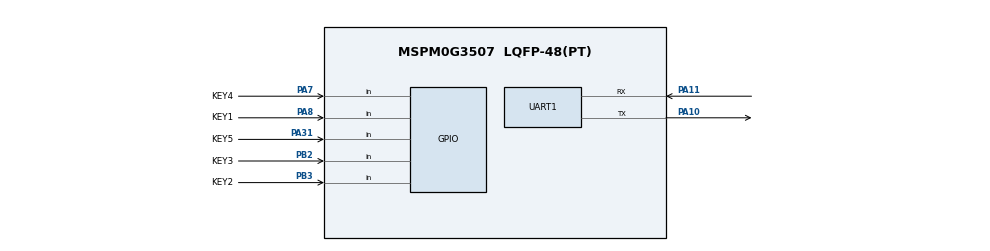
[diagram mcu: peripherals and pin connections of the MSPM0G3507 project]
/**
 * AI AGENTS: Do not edit this file directly. There is no validation or error feedback when
 * editing manually — mistakes will be silent until the file is loaded in SysConfig.
 * Use the SysConfig MCP server instead to make changes with immediate error reporting.
 *
 * These arguments were used when this file was generated. They will be automatically applied on subsequent loads
 * via the GUI or CLI. Run CLI with '--help' for additional information on how to override these arguments.
 * @cliArgs --device "MSPM0G350X" --part "Default" --package "LQFP-48(PT)" --product "mspm0_sdk@2.05.00.05"
 * @v2CliArgs --device "MSPM0G3507" --package "LQFP-48(PT)" --product "mspm0_sdk@2.05.00.05"
 * @versions {"tool":"1.28.0+4712"}
 */

/**
 * Import the modules used in this configuration.
 */
const ADC12  = scripting.addModule("/ti/driverlib/ADC12", {}, false);
const ADC121 = ADC12.addInstance();
const ADC122 = ADC12.addInstance();
const Board  = scripting.addModule("/ti/driverlib/Board");
const DAC12  = scripting.addModule("/ti/driverlib/DAC12");
const DMA    = scripting.addModule("/ti/driverlib/DMA");
const GPIO   = scripting.addModule("/ti/driverlib/GPIO", {}, false);
const GPIO1  = GPIO.addInstance();
const PWM    = scripting.addModule("/ti/driverlib/PWM", {}, false);
const PWM1   = PWM.addInstance();
const SYSCTL = scripting.addModule("/ti/driverlib/SYSCTL");
const TIMER  = scripting.addModule("/ti/driverlib/TIMER", {}, false);
const TIMER1 = TIMER.addInstance();
const TIMER2 = TIMER.addInstance();
const UART   = scripting.addModule("/ti/driverlib/UART", {}, false);
const UART1  = UART.addInstance();
const VREF   = scripting.addModule("/ti/driverlib/VREF");

/**
 * Write custom configuration values to the imported modules.
 */
const gate8  = system.clockTree["MFPCLKGATE"];
gate8.enable = true;

ADC121.$name                          = "ADC12_0";
ADC121.repeatMode                     = true;
ADC121.trigSrc                        = "DL_ADC12_TRIG_SRC_EVENT";
ADC121.adcMem0chansel                 = "DL_ADC12_INPUT_CHAN_7";
ADC121.adcMem0vref                    = "DL_ADC12_REFERENCE_VOLTAGE_INTREF";
ADC121.sampleTime0                    = "500ns";
ADC121.powerDownMode                  = "DL_ADC12_POWER_DOWN_MODE_MANUAL";
ADC121.configureDMA                   = true;
ADC121.sampCnt                        = 1;
ADC121.enabledDMATriggers             = ["DL_ADC12_DMA_MEM0_RESULT_LOADED"];
ADC121.enabledInterrupts              = ["DL_ADC12_INTERRUPT_DMA_DONE"];
ADC121.subChanID                      = 1;
ADC121.peripheral.$assign             = "ADC0";
ADC121.peripheral.adcPin7.$assign     = "PA22";
ADC121.adcPin7Config.$name            = "ti_driverlib_gpio_GPIOPinGeneric0";
ADC121.DMA_CHANNEL.$name              = "DMA_CH0";
ADC121.DMA_CHANNEL.addressMode        = "f2b";
ADC121.DMA_CHANNEL.srcLength          = "HALF_WORD";
ADC121.DMA_CHANNEL.dstLength          = "HALF_WORD";
ADC121.DMA_CHANNEL.transferMode       = "FULL_CH_REPEAT_SINGLE";
ADC121.DMA_CHANNEL.peripheral.$assign = "DMA_CH0";

ADC122.$name                          = "ADC12_1";
ADC122.repeatMode                     = true;
ADC122.trigSrc                        = "DL_ADC12_TRIG_SRC_EVENT";
ADC122.adcMem0chansel                 = "DL_ADC12_INPUT_CHAN_7";
ADC122.adcMem0vref                    = "DL_ADC12_REFERENCE_VOLTAGE_INTREF";
ADC122.sampleTime0                    = "500ns";
ADC122.powerDownMode                  = "DL_ADC12_POWER_DOWN_MODE_MANUAL";
ADC122.configureDMA                   = true;
ADC122.sampCnt                        = 1;
ADC122.enabledDMATriggers             = ["DL_ADC12_DMA_MEM0_RESULT_LOADED"];
ADC122.enabledInterrupts              = ["DL_ADC12_INTERRUPT_DMA_DONE"];
ADC122.subChanID                      = 2;
ADC122.peripheral.$assign             = "ADC1";
ADC122.peripheral.adcPin7.$assign     = "PA21";
ADC122.adcPin7Config.$name            = "ti_driverlib_gpio_GPIOPinGeneric1";
ADC122.DMA_CHANNEL.$name              = "DMA_CH1";
ADC122.DMA_CHANNEL.addressMode        = "f2b";
ADC122.DMA_CHANNEL.srcLength          = "HALF_WORD";
ADC122.DMA_CHANNEL.dstLength          = "HALF_WORD";
ADC122.DMA_CHANNEL.transferMode       = "FULL_CH_REPEAT_SINGLE";
ADC122.DMA_CHANNEL.peripheral.$assign = "DMA_CH1";


DAC12.dacOutputPinEn     = true;
DAC12.dacConfigureDMA    = true;
DAC12.dacSampleTimerEn   = false;
DAC12.dacSampleTimerRate = "1M";
DAC12.dacOutput12        = 2048;
DAC12.dacFIFOEn          = true;
DAC12.dacAmplifier       = "ON";
DAC12.dacFIFOThresh      = "TWO_QTRS_EMPTY";
DAC12.DMA_CHANNEL.$name  = "DMA_DAC";
DAC12.DMA_CHANNEL.transferMode = "FULL_CH_REPEAT_SINGLE";
DAC12.DMA_CHANNEL.addressMode = "b2f";
DAC12.DMA_CHANNEL.srcLength = "HALF_WORD";
DAC12.DMA_CHANNEL.dstLength = "HALF_WORD";
DAC12.DMA_CHANNEL.peripheral.$assign = "DMA_CH2";
DAC12.OutPinConfig.$name = "ti_driverlib_gpio_GPIOPinGeneric4";


GPIO1.$name                              = "KEY";
GPIO1.associatedPins.create(5);
GPIO1.associatedPins[0].$name            = "KEY1";
GPIO1.associatedPins[0].direction        = "INPUT";
GPIO1.associatedPins[0].assignedPort     = "PORTA";
GPIO1.associatedPins[0].assignedPin      = "8";
GPIO1.associatedPins[0].internalResistor = "PULL_UP";
GPIO1.associatedPins[0].pin.$assign      = "PA8";
GPIO1.associatedPins[1].$name            = "KEY2";
GPIO1.associatedPins[1].direction        = "INPUT";
GPIO1.associatedPins[1].assignedPort     = "PORTB";
GPIO1.associatedPins[1].assignedPin      = "3";
GPIO1.associatedPins[1].internalResistor = "PULL_UP";
GPIO1.associatedPins[1].pin.$assign      = "PB3";
GPIO1.associatedPins[2].$name            = "KEY3";
GPIO1.associatedPins[2].direction        = "INPUT";
GPIO1.associatedPins[2].assignedPort     = "PORTB";
GPIO1.associatedPins[2].assignedPin      = "2";
GPIO1.associatedPins[2].internalResistor = "PULL_UP";
GPIO1.associatedPins[2].pin.$assign      = "PB2";
GPIO1.associatedPins[3].$name            = "KEY4";
GPIO1.associatedPins[3].direction        = "INPUT";
GPIO1.associatedPins[3].assignedPort     = "PORTA";
GPIO1.associatedPins[3].assignedPin      = "7";
GPIO1.associatedPins[3].internalResistor = "PULL_UP";
GPIO1.associatedPins[3].pin.$assign      = "PA7";
GPIO1.associatedPins[4].$name            = "KEY5";
GPIO1.associatedPins[4].direction        = "INPUT";
GPIO1.associatedPins[4].assignedPort     = "PORTA";
GPIO1.associatedPins[4].assignedPin      = "31";
GPIO1.associatedPins[4].internalResistor = "PULL_UP";
GPIO1.associatedPins[4].pin.$assign      = "PA31";

PWM1.$name                   = "PWM_0";
PWM1.PWM_CHANNEL_0.$name     = "ti_driverlib_pwm_PWMTimerCC0";
PWM1.PWM_CHANNEL_0.dutyCycle = 50;
PWM1.PWM_CHANNEL_1.$name     = "ti_driverlib_pwm_PWMTimerCC1";
PWM1.PWM_CHANNEL_1.dutyCycle = 50;
PWM1.ccp0PinConfig.$name     = "ti_driverlib_gpio_GPIOPinGeneric5";
PWM1.ccp1PinConfig.$name     = "ti_driverlib_gpio_GPIOPinGeneric6";

SYSCTL.forceDefaultClkConfig = true;
SYSCTL.clockTreeEn           = true;
SYSCTL.MFPCLKEn              = true;
/* Manual 8MHz project clock note:
 * ti_msp_dl_config.c keeps SYSOSC at 32MHz and applies MCLK divider /4.
 * If this SysConfig file is regenerated, keep CPUCLK/BUSCLK at 8MHz and
 * preserve UART/SPI/timer recalculations in generated code.
 */

VREF.basicVREFEnable     = true;
VREF.basicVREFOutput     = "DL_VREF_BUFCONFIG_OUTPUT_2_5V";
VREF.basicSHModeEnable   = false;
VREF.peripheral.$assign  = "VREF";

TIMER1.$name                       = "ADC_SAMPLE_TIMER";
TIMER1.timerPeriod                 = "78.125 us";
TIMER1.event1PublisherChannel      = 1;
TIMER1.event1ControllerInterruptEn = ["ZERO_EVENT"];
TIMER1.event2PublisherChannel      = 2;
TIMER1.event2ControllerInterruptEn = ["ZERO_EVENT"];
TIMER1.peripheral.$assign          = "TIMG0";

TIMER2.$name           = "DAC_TIMER";
TIMER2.timerMode       = "PERIODIC";
TIMER2.timerStartTimer = false;
TIMER2.event1PublisherChannel = 3;
TIMER2.event1ControllerInterruptEn = ["ZERO_EVENT"];

UART1.$name                            = "UART_DEBUG";
UART1.targetBaudRate                   = 115200;
UART1.enableFIFO                       = true;
UART1.enabledInterrupts                = ["RX"];
UART1.peripheral.$assign               = "UART0";
UART1.peripheral.rxPin.$assign         = "PA11";
UART1.peripheral.txPin.$assign         = "PA10";
UART1.txPinConfig.$name                = "ti_driverlib_gpio_GPIOPinGeneric2";
UART1.txPinConfig.direction            = scripting.forceWrite("OUTPUT");
UART1.txPinConfig.hideOutputInversion  = scripting.forceWrite(false);
UART1.txPinConfig.onlyInternalResistor = scripting.forceWrite(false);
UART1.txPinConfig.passedPeripheralType = scripting.forceWrite("Digital");
UART1.rxPinConfig.$name                = "ti_driverlib_gpio_GPIOPinGeneric3";
UART1.rxPinConfig.hideOutputInversion  = scripting.forceWrite(false);
UART1.rxPinConfig.onlyInternalResistor = scripting.forceWrite(false);
UART1.rxPinConfig.passedPeripheralType = scripting.forceWrite("Digital");

/**
 * Pinmux solution for unlocked pins/peripherals. This ensures that minor changes to the automatic solver in a future
 * version of the tool will not impact the pinmux you originally saw.  These lines can be completely deleted in order to
 * re-solve from scratch.
 */
Board.peripheral.$suggestSolution                     = "DEBUGSS";
Board.peripheral.swclkPin.$suggestSolution            = "PA20";
Board.peripheral.swdioPin.$suggestSolution            = "PA19";
DAC12.peripheral.$suggestSolution                     = "DAC0";
DAC12.peripheral.OutPin.$suggestSolution              = "PA15";
DMA.associatedChannels[0].peripheral.$suggestSolution = "DMA_CH2";
PWM1.peripheral.$suggestSolution                      = "TIMA0";
PWM1.peripheral.ccp0Pin.$suggestSolution              = "PA0";
PWM1.peripheral.ccp1Pin.$suggestSolution              = "PA1";
TIMER2.peripheral.$suggestSolution                    = "TIMA1";
